VERSION ""

NS_ :

BS_:

BU_: BMS

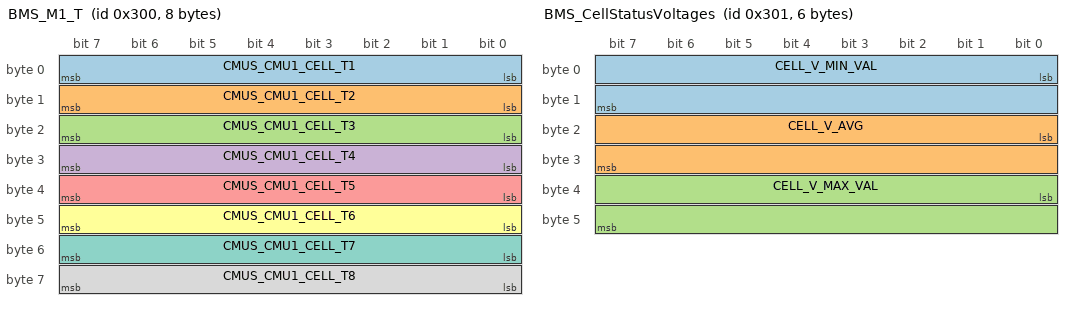
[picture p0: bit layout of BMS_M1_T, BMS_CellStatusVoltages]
BO_ 768 BMS_M1_T: 8 BMS
 SG_ CMUS_CMU1_CELL_T1 : 0|8@1- (1,0) [10|70] "degC" Vector__XXX
 SG_ CMUS_CMU1_CELL_T2 : 8|8@1- (1,0) [10|70] "degC" Vector__XXX
 SG_ CMUS_CMU1_CELL_T3 : 16|8@1- (1,0) [10|70] "degC" Vector__XXX
 SG_ CMUS_CMU1_CELL_T4 : 24|8@1- (1,0) [10|70] "degC" Vector__XXX
 SG_ CMUS_CMU1_CELL_T5 : 32|8@1- (1,0) [10|70] "degC" Vector__XXX
 SG_ CMUS_CMU1_CELL_T6 : 40|8@1- (1,0) [10|70] "degC" Vector__XXX
 SG_ CMUS_CMU1_CELL_T7 : 48|8@1- (1,0) [10|70] "degC" Vector__XXX
 SG_ CMUS_CMU1_CELL_T8 : 56|8@1- (1,0) [10|70] "degC" Vector__XXX

BO_ 3221225472 VECTOR__INDEPENDENT_SIG_MSG: 0 Vector__XXX
 SG_ NewSignal_0001 : 0|8@1+ (1,0) [0|0] "" Vector__XXX

BO_ 769 BMS_CellStatusVoltages: 6 BMS
 SG_ CELL_V_MIN_VAL : 0|16@1+ (0.1,0) [2000|4000] "mV" Vector__XXX
 SG_ CELL_V_AVG : 16|16@1+ (0.1,0) [2000|4000] "mV" Vector__XXX
 SG_ CELL_V_MAX_VAL : 32|16@1+ (0.1,0) [2000|4000] "mV" Vector__XXX

BO_ 770 BMS_BattStatus: 4 BMS
 SG_ PACK_V_SUM_OF_CELLS : 0|16@1+ (0.1,0) [0|400] "V" Vector__XXX
 SG_ PACK_Q_SOC_TRIMMED : 16|16@1+ (0.01,0) [0|100] "%" Vector__XXX

BA_DEF_  "BusType" STRING ;
BA_DEF_DEF_  "BusType" "CAN";
